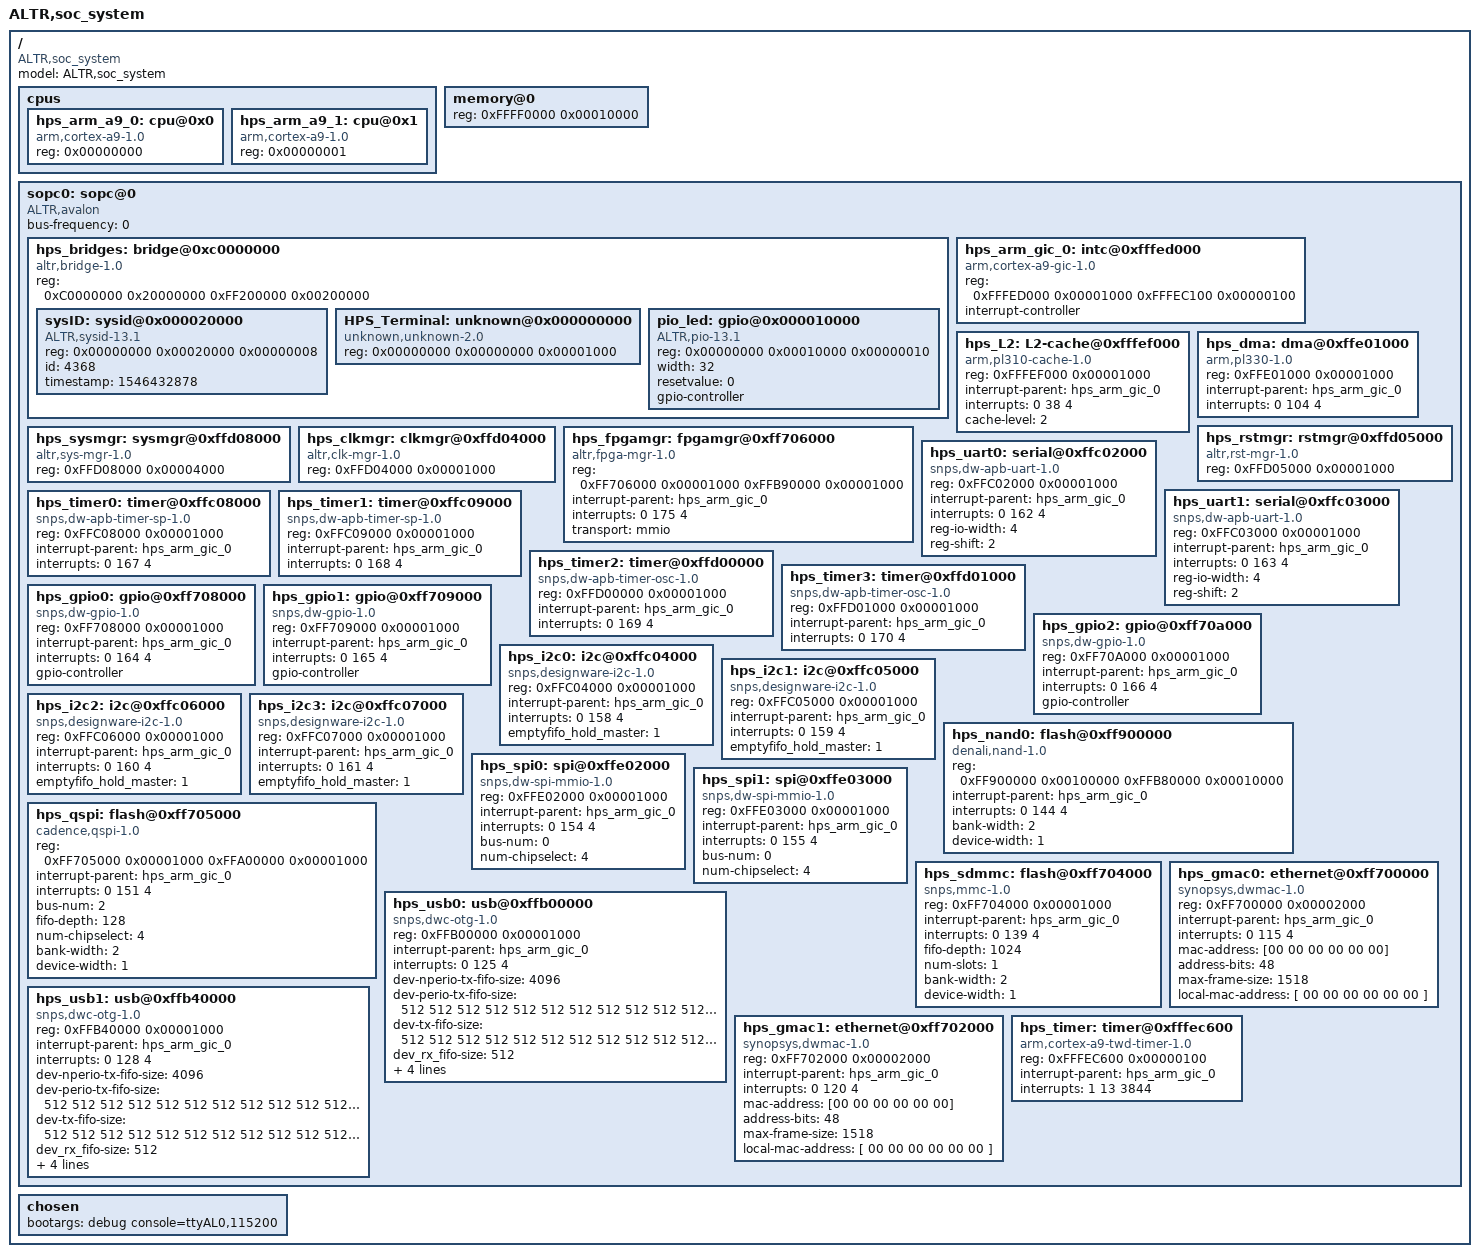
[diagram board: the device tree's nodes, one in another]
/*
 * This devicetree is generated by sopc2dts on Sun Jan 13 17:24:45 CST 2019
 * Sopc2dts is written by Walter Goossens <waltergoossens@home.nl>
 * in cooperation with the nios2 community <Nios2-dev@sopc.et.ntust.edu.tw>
 */
/dts-v1/;

/ {
	model = "ALTR,soc_system";
	compatible = "ALTR,soc_system";
	#address-cells = < 1 >;
	#size-cells = < 1 >;

	cpus {
		#address-cells = < 1 >;
		#size-cells = < 0 >;

		hps_arm_a9_0: cpu@0x0 {
			device_type = "cpu";
			compatible = "arm,cortex-a9-1.0", "arm,cortex-a9";
			reg = < 0x00000000 >;
		}; //end cpu@0x0 (hps_arm_a9_0)

		hps_arm_a9_1: cpu@0x1 {
			device_type = "cpu";
			compatible = "arm,cortex-a9-1.0", "arm,cortex-a9";
			reg = < 0x00000001 >;
		}; //end cpu@0x1 (hps_arm_a9_1)
	}; //end cpus

	memory@0 {
		device_type = "memory";
		reg = < 0xFFFF0000 0x00010000 >;
	}; //end memory@0

	sopc0: sopc@0 {
		device_type = "soc";
		ranges;
		#address-cells = < 1 >;
		#size-cells = < 1 >;
		compatible = "ALTR,avalon", "simple-bus";
		bus-frequency = < 0 >;

		hps_bridges: bridge@0xc0000000 {
			compatible = "altr,bridge-1.0", "simple-bus";
			reg = < 0xC0000000 0x20000000 
				0xFF200000 0x00200000 >;
			reg-names = "axi_h2f", "axi_h2f_lw";
			#address-cells = < 2 >;
			#size-cells = < 1 >;
			ranges = < 0x00000000 0x00020000 0xC0020000 0x00000008 
				0x00000000 0x00000000 0xC0000000 0x00001000 
				0x00000000 0x00010000 0xC0010000 0x00000010 >;

			sysID: sysid@0x000020000 {
				compatible = "ALTR,sysid-13.1", "ALTR,sysid-1.0", "altr,sysid-1.0";
				reg = < 0x00000000 0x00020000 0x00000008 >;
				id = < 4368 >;	/* embeddedsw.dts.params.id type NUMBER */
				timestamp = < 1546432878 >;	/* embeddedsw.dts.params.timestamp type NUMBER */
			}; //end sysid@0x000020000 (sysID)

			HPS_Terminal: unknown@0x000000000 {
				compatible = "unknown,unknown-2.0";
				reg = < 0x00000000 0x00000000 0x00001000 >;
			}; //end unknown@0x000000000 (HPS_Terminal)

			pio_led: gpio@0x000010000 {
				compatible = "ALTR,pio-13.1", "ALTR,pio-1.0", "altr,pio-1.0";
				reg = < 0x00000000 0x00010000 0x00000010 >;
				width = < 32 >;	/* embeddedsw.dts.params.width type NUMBER */
				resetvalue = < 0 >;	/* embeddedsw.dts.params.resetvalue type NUMBER */
				#gpio-cells = < 2 >;
				gpio-controller;
			}; //end gpio@0x000010000 (pio_led)
		}; //end bridge@0xc0000000 (hps_bridges)

		hps_arm_gic_0: intc@0xfffed000 {
			compatible = "arm,cortex-a9-gic-1.0", "arm,cortex-a9-gic";
			reg = < 0xFFFED000 0x00001000 
				0xFFFEC100 0x00000100 >;
			reg-names = "axi_slave0", "axi_slave1";
			interrupt-controller;
			#interrupt-cells = < 3 >;
		}; //end intc@0xfffed000 (hps_arm_gic_0)

		hps_L2: L2-cache@0xfffef000 {
			compatible = "arm,pl310-cache-1.0", "arm,pl310-cache";
			reg = < 0xFFFEF000 0x00001000 >;
			interrupt-parent = < &hps_arm_gic_0 >;
			interrupts = < 0 38 4 >;
			cache-level = < 2 >;	/* embeddedsw.dts.params.cache-level type NUMBER */
		}; //end L2-cache@0xfffef000 (hps_L2)

		hps_dma: dma@0xffe01000 {
			compatible = "arm,pl330-1.0", "arm,pl330", "arm,primecell";
			reg = < 0xFFE01000 0x00001000 >;
			interrupt-parent = < &hps_arm_gic_0 >;
			interrupts = < 0 104 4 >;
		}; //end dma@0xffe01000 (hps_dma)

		hps_sysmgr: sysmgr@0xffd08000 {
			compatible = "altr,sys-mgr-1.0", "altr,sys-mgr";
			reg = < 0xFFD08000 0x00004000 >;
		}; //end sysmgr@0xffd08000 (hps_sysmgr)

		hps_clkmgr: clkmgr@0xffd04000 {
			compatible = "altr,clk-mgr-1.0", "altr,clk-mgr";
			reg = < 0xFFD04000 0x00001000 >;
		}; //end clkmgr@0xffd04000 (hps_clkmgr)

		hps_rstmgr: rstmgr@0xffd05000 {
			compatible = "altr,rst-mgr-1.0", "altr,rst-mgr";
			reg = < 0xFFD05000 0x00001000 >;
		}; //end rstmgr@0xffd05000 (hps_rstmgr)

		hps_fpgamgr: fpgamgr@0xff706000 {
			compatible = "altr,fpga-mgr-1.0", "altr,fpga-mgr";
			reg = < 0xFF706000 0x00001000 
				0xFFB90000 0x00001000 >;
			reg-names = "axi_slave0", "axi_slave1";
			interrupt-parent = < &hps_arm_gic_0 >;
			interrupts = < 0 175 4 >;
			transport = "mmio";	/* embeddedsw.dts.params.transport type STRING */
		}; //end fpgamgr@0xff706000 (hps_fpgamgr)

		hps_uart0: serial@0xffc02000 {
			compatible = "snps,dw-apb-uart-1.0", "snps,dw-apb-uart";
			reg = < 0xFFC02000 0x00001000 >;
			interrupt-parent = < &hps_arm_gic_0 >;
			interrupts = < 0 162 4 >;
			reg-io-width = < 4 >;	/* embeddedsw.dts.params.reg-io-width type NUMBER */
			reg-shift = < 2 >;	/* embeddedsw.dts.params.reg-shift type NUMBER */
		}; //end serial@0xffc02000 (hps_uart0)

		hps_uart1: serial@0xffc03000 {
			compatible = "snps,dw-apb-uart-1.0", "snps,dw-apb-uart";
			reg = < 0xFFC03000 0x00001000 >;
			interrupt-parent = < &hps_arm_gic_0 >;
			interrupts = < 0 163 4 >;
			reg-io-width = < 4 >;	/* embeddedsw.dts.params.reg-io-width type NUMBER */
			reg-shift = < 2 >;	/* embeddedsw.dts.params.reg-shift type NUMBER */
		}; //end serial@0xffc03000 (hps_uart1)

		hps_timer0: timer@0xffc08000 {
			compatible = "snps,dw-apb-timer-sp-1.0", "snps,dw-apb-timer-sp";
			reg = < 0xFFC08000 0x00001000 >;
			interrupt-parent = < &hps_arm_gic_0 >;
			interrupts = < 0 167 4 >;
		}; //end timer@0xffc08000 (hps_timer0)

		hps_timer1: timer@0xffc09000 {
			compatible = "snps,dw-apb-timer-sp-1.0", "snps,dw-apb-timer-sp";
			reg = < 0xFFC09000 0x00001000 >;
			interrupt-parent = < &hps_arm_gic_0 >;
			interrupts = < 0 168 4 >;
		}; //end timer@0xffc09000 (hps_timer1)

		hps_timer2: timer@0xffd00000 {
			compatible = "snps,dw-apb-timer-osc-1.0", "snps,dw-apb-timer-osc";
			reg = < 0xFFD00000 0x00001000 >;
			interrupt-parent = < &hps_arm_gic_0 >;
			interrupts = < 0 169 4 >;
		}; //end timer@0xffd00000 (hps_timer2)

		hps_timer3: timer@0xffd01000 {
			compatible = "snps,dw-apb-timer-osc-1.0", "snps,dw-apb-timer-osc";
			reg = < 0xFFD01000 0x00001000 >;
			interrupt-parent = < &hps_arm_gic_0 >;
			interrupts = < 0 170 4 >;
		}; //end timer@0xffd01000 (hps_timer3)

		hps_gpio0: gpio@0xff708000 {
			compatible = "snps,dw-gpio-1.0", "snps,dw-gpio";
			reg = < 0xFF708000 0x00001000 >;
			interrupt-parent = < &hps_arm_gic_0 >;
			interrupts = < 0 164 4 >;
			#gpio-cells = < 2 >;
			gpio-controller;
		}; //end gpio@0xff708000 (hps_gpio0)

		hps_gpio1: gpio@0xff709000 {
			compatible = "snps,dw-gpio-1.0", "snps,dw-gpio";
			reg = < 0xFF709000 0x00001000 >;
			interrupt-parent = < &hps_arm_gic_0 >;
			interrupts = < 0 165 4 >;
			#gpio-cells = < 2 >;
			gpio-controller;
		}; //end gpio@0xff709000 (hps_gpio1)

		hps_gpio2: gpio@0xff70a000 {
			compatible = "snps,dw-gpio-1.0", "snps,dw-gpio";
			reg = < 0xFF70A000 0x00001000 >;
			interrupt-parent = < &hps_arm_gic_0 >;
			interrupts = < 0 166 4 >;
			#gpio-cells = < 2 >;
			gpio-controller;
		}; //end gpio@0xff70a000 (hps_gpio2)

		hps_i2c0: i2c@0xffc04000 {
			compatible = "snps,designware-i2c-1.0", "snps,designware-i2c";
			reg = < 0xFFC04000 0x00001000 >;
			interrupt-parent = < &hps_arm_gic_0 >;
			interrupts = < 0 158 4 >;
			emptyfifo_hold_master = < 1 >;	/* embeddedsw.dts.params.emptyfifo_hold_master type NUMBER */
		}; //end i2c@0xffc04000 (hps_i2c0)

		hps_i2c1: i2c@0xffc05000 {
			compatible = "snps,designware-i2c-1.0", "snps,designware-i2c";
			reg = < 0xFFC05000 0x00001000 >;
			interrupt-parent = < &hps_arm_gic_0 >;
			interrupts = < 0 159 4 >;
			emptyfifo_hold_master = < 1 >;	/* embeddedsw.dts.params.emptyfifo_hold_master type NUMBER */
		}; //end i2c@0xffc05000 (hps_i2c1)

		hps_i2c2: i2c@0xffc06000 {
			compatible = "snps,designware-i2c-1.0", "snps,designware-i2c";
			reg = < 0xFFC06000 0x00001000 >;
			interrupt-parent = < &hps_arm_gic_0 >;
			interrupts = < 0 160 4 >;
			emptyfifo_hold_master = < 1 >;	/* embeddedsw.dts.params.emptyfifo_hold_master type NUMBER */
		}; //end i2c@0xffc06000 (hps_i2c2)

		hps_i2c3: i2c@0xffc07000 {
			compatible = "snps,designware-i2c-1.0", "snps,designware-i2c";
			reg = < 0xFFC07000 0x00001000 >;
			interrupt-parent = < &hps_arm_gic_0 >;
			interrupts = < 0 161 4 >;
			emptyfifo_hold_master = < 1 >;	/* embeddedsw.dts.params.emptyfifo_hold_master type NUMBER */
		}; //end i2c@0xffc07000 (hps_i2c3)

		hps_nand0: flash@0xff900000 {
			compatible = "denali,nand-1.0", "denali,denali-nand-dt";
			reg = < 0xFF900000 0x00100000 
				0xFFB80000 0x00010000 >;
			reg-names = "nand_data", "denali_reg";	/* embeddedsw.dts.params.reg-names type STRING */
			interrupt-parent = < &hps_arm_gic_0 >;
			interrupts = < 0 144 4 >;
			#adress-cells = < 1 >;	/* embeddedsw.dts.params.#adress-cells type NUMBER */
			#size-cells = < 1 >;	/* embeddedsw.dts.params.#size-cells type NUMBER */
			bank-width = < 2 >;
			device-width = < 1 >;
		}; //end flash@0xff900000 (hps_nand0)

		hps_spi0: spi@0xffe02000 {
			compatible = "snps,dw-spi-mmio-1.0", "snps,dw-spi-mmio";
			reg = < 0xFFE02000 0x00001000 >;
			interrupt-parent = < &hps_arm_gic_0 >;
			interrupts = < 0 154 4 >;
			#address-cells = < 1 >;	/* embeddedsw.dts.params.#address-cells type NUMBER */
			#size-cells = < 0 >;	/* embeddedsw.dts.params.#size-cells type NUMBER */
			bus-num = < 0 >;	/* embeddedsw.dts.params.bus-num type NUMBER */
			num-chipselect = < 4 >;	/* embeddedsw.dts.params.num-chipselect type NUMBER */
		}; //end spi@0xffe02000 (hps_spi0)

		hps_spi1: spi@0xffe03000 {
			compatible = "snps,dw-spi-mmio-1.0", "snps,dw-spi-mmio";
			reg = < 0xFFE03000 0x00001000 >;
			interrupt-parent = < &hps_arm_gic_0 >;
			interrupts = < 0 155 4 >;
			#address-cells = < 1 >;	/* embeddedsw.dts.params.#address-cells type NUMBER */
			#size-cells = < 0 >;	/* embeddedsw.dts.params.#size-cells type NUMBER */
			bus-num = < 0 >;	/* embeddedsw.dts.params.bus-num type NUMBER */
			num-chipselect = < 4 >;	/* embeddedsw.dts.params.num-chipselect type NUMBER */
		}; //end spi@0xffe03000 (hps_spi1)

		hps_qspi: flash@0xff705000 {
			compatible = "cadence,qspi-1.0", "cadence,qspi";
			reg = < 0xFF705000 0x00001000 
				0xFFA00000 0x00001000 >;
			reg-names = "axi_slave0", "axi_slave1";
			interrupt-parent = < &hps_arm_gic_0 >;
			interrupts = < 0 151 4 >;
			bus-num = < 2 >;	/* embeddedsw.dts.params.bus-num type NUMBER */
			fifo-depth = < 128 >;	/* embeddedsw.dts.params.fifo-depth type NUMBER */
			num-chipselect = < 4 >;	/* embeddedsw.dts.params.num-chipselect type NUMBER */
			bank-width = < 2 >;
			device-width = < 1 >;
		}; //end flash@0xff705000 (hps_qspi)

		hps_sdmmc: flash@0xff704000 {
			compatible = "snps,mmc-1.0", "snps,dw-mshc";
			reg = < 0xFF704000 0x00001000 >;
			interrupt-parent = < &hps_arm_gic_0 >;
			interrupts = < 0 139 4 >;
			fifo-depth = < 1024 >;	/* embeddedsw.dts.params.fifo-depth type NUMBER */
			num-slots = < 1 >;	/* embeddedsw.dts.params.num-slots type NUMBER */
			bank-width = < 2 >;
			device-width = < 1 >;
		}; //end flash@0xff704000 (hps_sdmmc)

		hps_usb0: usb@0xffb00000 {
			compatible = "snps,dwc-otg-1.0", "snps,dwc-otg";
			reg = < 0xFFB00000 0x00001000 >;
			interrupt-parent = < &hps_arm_gic_0 >;
			interrupts = < 0 125 4 >;
			dev-nperio-tx-fifo-size = < 4096 >;	/* embeddedsw.dts.params.dev-nperio-tx-fifo-size type NUMBER */
			dev-perio-tx-fifo-size = "<512 512 512 512 512 512 512 512 512 512 512 512 512 512 512>";	/* embeddedsw.dts.params.dev-perio-tx-fifo-size type STRING */
			dev-tx-fifo-size = "<512 512 512 512 512 512 512 512 512 512 512 512 512 512 512>";	/* embeddedsw.dts.params.dev-tx-fifo-size type STRING */
			dev_rx_fifo-size = < 512 >;	/* embeddedsw.dts.params.dev_rx_fifo-size type NUMBER */
			dma-mask = < 268435455 >;	/* embeddedsw.dts.params.dma-mask type NUMBER */
			host_rx_fifo-size = < 512 >;	/* embeddedsw.dts.params.host_rx_fifo-size type NUMBER */
			ulpi-ddr = < 0 >;	/* embeddedsw.dts.params.ulpi-ddr type NUMBER */
			voltage-switch = < 0 >;	/* embeddedsw.dts.params.voltage-switch type NUMBER */
		}; //end usb@0xffb00000 (hps_usb0)

		hps_usb1: usb@0xffb40000 {
			compatible = "snps,dwc-otg-1.0", "snps,dwc-otg";
			reg = < 0xFFB40000 0x00001000 >;
			interrupt-parent = < &hps_arm_gic_0 >;
			interrupts = < 0 128 4 >;
			dev-nperio-tx-fifo-size = < 4096 >;	/* embeddedsw.dts.params.dev-nperio-tx-fifo-size type NUMBER */
			dev-perio-tx-fifo-size = "<512 512 512 512 512 512 512 512 512 512 512 512 512 512 512>";	/* embeddedsw.dts.params.dev-perio-tx-fifo-size type STRING */
			dev-tx-fifo-size = "<512 512 512 512 512 512 512 512 512 512 512 512 512 512 512>";	/* embeddedsw.dts.params.dev-tx-fifo-size type STRING */
			dev_rx_fifo-size = < 512 >;	/* embeddedsw.dts.params.dev_rx_fifo-size type NUMBER */
			dma-mask = < 268435455 >;	/* embeddedsw.dts.params.dma-mask type NUMBER */
			host_rx_fifo-size = < 512 >;	/* embeddedsw.dts.params.host_rx_fifo-size type NUMBER */
			ulpi-ddr = < 0 >;	/* embeddedsw.dts.params.ulpi-ddr type NUMBER */
			voltage-switch = < 0 >;	/* embeddedsw.dts.params.voltage-switch type NUMBER */
		}; //end usb@0xffb40000 (hps_usb1)

		hps_gmac0: ethernet@0xff700000 {
			compatible = "synopsys,dwmac-1.0", "altr,socfpga-stmmac", "snps,dwmac-3.70a", "snps,dwmac";
			reg = < 0xFF700000 0x00002000 >;
			interrupt-parent = < &hps_arm_gic_0 >;
			interrupts = < 0 115 4 >;
			interrupt-names = "macirq";	/* embeddedsw.dts.params.interrupt-names type STRING */
			mac-address = "[00 00 00 00 00 00]";	/* embeddedsw.dts.params.mac-address type STRING */
			address-bits = < 48 >;
			max-frame-size = < 1518 >;
			local-mac-address = [ 00 00 00 00 00 00 ];
		}; //end ethernet@0xff700000 (hps_gmac0)

		hps_gmac1: ethernet@0xff702000 {
			compatible = "synopsys,dwmac-1.0", "altr,socfpga-stmmac", "snps,dwmac-3.70a", "snps,dwmac";
			reg = < 0xFF702000 0x00002000 >;
			interrupt-parent = < &hps_arm_gic_0 >;
			interrupts = < 0 120 4 >;
			interrupt-names = "macirq";	/* embeddedsw.dts.params.interrupt-names type STRING */
			mac-address = "[00 00 00 00 00 00]";	/* embeddedsw.dts.params.mac-address type STRING */
			address-bits = < 48 >;
			max-frame-size = < 1518 >;
			local-mac-address = [ 00 00 00 00 00 00 ];
		}; //end ethernet@0xff702000 (hps_gmac1)

		hps_timer: timer@0xfffec600 {
			compatible = "arm,cortex-a9-twd-timer-1.0", "arm,cortex-a9-twd-timer";
			reg = < 0xFFFEC600 0x00000100 >;
			interrupt-parent = < &hps_arm_gic_0 >;
			interrupts = < 1 13 3844 >;
		}; //end timer@0xfffec600 (hps_timer)
	}; //end sopc@0 (sopc0)

	chosen {
		bootargs = "debug console=ttyAL0,115200";
	}; //end chosen
}; //end /
